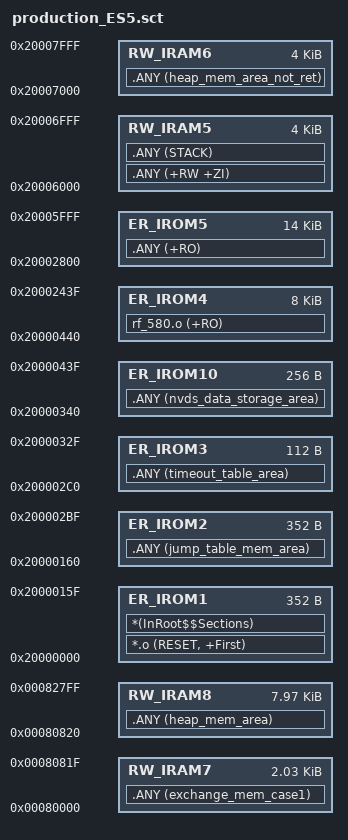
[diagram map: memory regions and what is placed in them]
#! armcc -E -I./ --cpu Cortex-M0

#include "da14580_config.h"

; *************************************************************
; *** Scatter-Loading Description File generated by uVision ***
; *************************************************************

LR_IROM1 0x20000000 0x00000160 {  ; load region size_region
  ER_IROM1 0x20000000 0x00000160  {  ; load address = execution address
   *.o (RESET, +First)
   *(InRoot$$Sections)
  }
}
 
LR_IROM2  0x20000160 0x00160 {
ER_IROM2 0x20000160 0x00160  {
   .ANY (jump_table_mem_area) 
	
  }
}

LR_IROM3 0x200002C0 0x070 {
 ER_IROM3 0x200002C0 0x070  {
   .ANY (timeout_table_area)
  }
}

LR_IROM10 0x20000340 0x0100 {
 ER_IROM10 0x20000340 0x0100  {
   .ANY (nvds_data_storage_area)
  }
}

LR_IROM4  0x20000440 0x2000 {
ER_IROM4 0x20000440 0x2000 {    
	rf_580.o (+RO)
	
  }
}

LR_IROM5 0x20002800 0x3800  {
ER_IROM5 0x20002800 0x3800  {
   .ANY (+RO)   
	
  }  
}  

LR_IRAM5  0x20006000 0x00001000 {

RW_IRAM5 0x20006000 0x00001000   {  ; RW data
   .ANY (+RW +ZI)
   .ANY (STACK)
  }
  
RW_IRAM6 0x20007000 0x00001000  {
   .ANY (heap_mem_area_not_ret)    
 }





RW_IRAM7 0x00080000 0x00000820  {
   .ANY (exchange_mem_case1) 
 }

RW_IRAM8 0x00080820 0x00001FE0  {
    .ANY (heap_mem_area)
  }  
}
